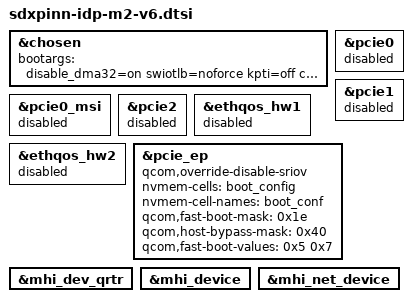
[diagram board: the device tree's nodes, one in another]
#include "sdxpinn-idp-mbb.dtsi"
#include "sdxpinn-idp-512mb.dtsi"

&chosen {
	bootargs = "disable_dma32=on swiotlb=noforce kpti=off cpufreq.default_governor=performance pcie_ports=compat msm_rtb.filter=0x237 reboot=w";
};

&pcie0 {
	status = "disabled";
};

&pcie0_msi {
	status = "disabled";
};

&pcie1 {
	status = "disabled";
};

&pcie2 {
	status = "disabled";
};

&ethqos_hw1 {
	status = "disabled";
};

&ethqos_hw2 {
	status = "disabled";
};

&pcie_ep {
	qcom,override-disable-sriov;
	nvmem-cells = <&boot_config>;
	nvmem-cell-names = "boot_conf";
	qcom,fast-boot-mask = <0x1e>;
	qcom,host-bypass-mask = <0x40>;
	qcom,fast-boot-values = <0x5 0x7>;
	status = "ok";
};

&mhi_dev_qrtr {
	status = "ok";
};

&mhi_device {
	status = "ok";
};

&mhi_net_device {
	status = "ok";
};

/delete-node/ &mdss_qpic;
